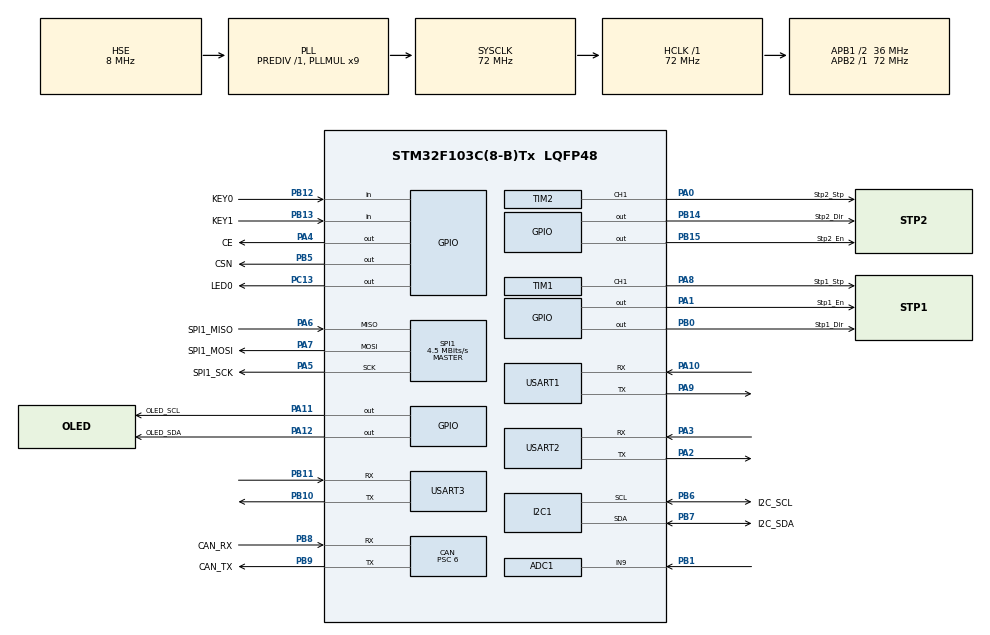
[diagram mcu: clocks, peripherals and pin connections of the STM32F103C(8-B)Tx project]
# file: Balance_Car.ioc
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ADC1.Channel-0\#ChannelRegularConversion=ADC_CHANNEL_9
ADC1.NbrOfConversionFlag=1
ADC1.Rank-0\#ChannelRegularConversion=1
ADC1.SamplingTime-0\#ChannelRegularConversion=ADC_SAMPLETIME_1CYCLE_5
ADC1.master=1
CAN.ABOM=ENABLE
CAN.BS1=CAN_BS1_9TQ
CAN.BS2=CAN_BS2_2TQ
CAN.CalculateBaudRate=499999
CAN.CalculateTimeBit=2000
CAN.CalculateTimeQuantum=166.66666666666669
CAN.NART=ENABLE
CAN.Prescaler=6
Dma.Request0=USART1_RX
Dma.Request1=USART1_TX
Dma.Request2=USART2_RX
Dma.Request3=USART2_TX
Dma.Request4=USART3_RX
Dma.Request5=USART3_TX
Dma.USART1_RX.0.Direction=DMA_PERIPH_TO_MEMORY
Dma.USART1_RX.0.Instance=DMA1_Channel5
Dma.USART1_RX.0.MemDataAlignment=DMA_MDATAALIGN_BYTE
Dma.USART1_RX.0.MemInc=DMA_MINC_ENABLE
Dma.USART1_RX.0.Mode=DMA_NORMAL
Dma.USART1_RX.0.PeriphDataAlignment=DMA_PDATAALIGN_BYTE
Dma.USART1_RX.0.PeriphInc=DMA_PINC_DISABLE
Dma.USART1_RX.0.Priority=DMA_PRIORITY_LOW
Dma.USART1_TX.1.Direction=DMA_MEMORY_TO_PERIPH
Dma.USART1_TX.1.Instance=DMA1_Channel4
Dma.USART1_TX.1.MemDataAlignment=DMA_MDATAALIGN_BYTE
Dma.USART1_TX.1.MemInc=DMA_MINC_ENABLE
Dma.USART1_TX.1.Mode=DMA_NORMAL
Dma.USART1_TX.1.PeriphDataAlignment=DMA_PDATAALIGN_BYTE
Dma.USART1_TX.1.PeriphInc=DMA_PINC_DISABLE
Dma.USART1_TX.1.Priority=DMA_PRIORITY_LOW
Dma.USART2_RX.2.Direction=DMA_PERIPH_TO_MEMORY
Dma.USART2_RX.2.Instance=DMA1_Channel6
Dma.USART2_RX.2.MemDataAlignment=DMA_MDATAALIGN_BYTE
Dma.USART2_RX.2.MemInc=DMA_MINC_ENABLE
Dma.USART2_RX.2.Mode=DMA_NORMAL
Dma.USART2_RX.2.PeriphDataAlignment=DMA_PDATAALIGN_BYTE
Dma.USART2_RX.2.PeriphInc=DMA_PINC_DISABLE
Dma.USART2_RX.2.Priority=DMA_PRIORITY_LOW
Dma.USART2_TX.3.Direction=DMA_MEMORY_TO_PERIPH
Dma.USART2_TX.3.Instance=DMA1_Channel7
Dma.USART2_TX.3.MemDataAlignment=DMA_MDATAALIGN_BYTE
Dma.USART2_TX.3.MemInc=DMA_MINC_ENABLE
Dma.USART2_TX.3.Mode=DMA_NORMAL
Dma.USART2_TX.3.PeriphDataAlignment=DMA_PDATAALIGN_BYTE
Dma.USART2_TX.3.PeriphInc=DMA_PINC_DISABLE
Dma.USART2_TX.3.Priority=DMA_PRIORITY_LOW
Dma.USART3_RX.4.Direction=DMA_PERIPH_TO_MEMORY
Dma.USART3_RX.4.Instance=DMA1_Channel3
Dma.USART3_RX.4.MemDataAlignment=DMA_MDATAALIGN_BYTE
Dma.USART3_RX.4.MemInc=DMA_MINC_ENABLE
Dma.USART3_RX.4.Mode=DMA_NORMAL
Dma.USART3_RX.4.PeriphDataAlignment=DMA_PDATAALIGN_BYTE
Dma.USART3_RX.4.PeriphInc=DMA_PINC_DISABLE
Dma.USART3_RX.4.Priority=DMA_PRIORITY_LOW
Dma.USART3_TX.5.Direction=DMA_MEMORY_TO_PERIPH
Dma.USART3_TX.5.Instance=DMA1_Channel2
Dma.USART3_TX.5.MemDataAlignment=DMA_MDATAALIGN_BYTE
Dma.USART3_TX.5.MemInc=DMA_MINC_ENABLE
Dma.USART3_TX.5.Mode=DMA_NORMAL
Dma.USART3_TX.5.PeriphDataAlignment=DMA_PDATAALIGN_BYTE
Dma.USART3_TX.5.PeriphInc=DMA_PINC_DISABLE
Dma.USART3_TX.5.Priority=DMA_PRIORITY_LOW
FREERTOS.TOTAL_HEAP_SIZE=6144
FREERTOS.Tasks01=defaultTask,24,128,StartDefaultTask,Default,NULL,Dynamic,NULL,NULL
FREERTOS.configGENERATE_RUN_TIME_STATS=1
FREERTOS.configTOTAL_HEAP_SIZE=6144
FREERTOS.configUSE_STATS_FORMATTING_FUNCTIONS=1
Mcu.Family=STM32F1
Mcu.Name=STM32F103C(8-B)Tx
Mcu.Package=LQFP48
NVIC.DMA1_Channel2_IRQn=true\:5\:0\:false\:false\:true\:true\:false\:true\:true
NVIC.DMA1_Channel3_IRQn=true\:5\:0\:false\:false\:true\:true\:false\:true\:true
NVIC.DMA1_Channel4_IRQn=true\:5\:0\:false\:false\:true\:true\:false\:true\:true
NVIC.DMA1_Channel5_IRQn=true\:5\:0\:false\:false\:true\:true\:false\:true\:true
NVIC.DMA1_Channel6_IRQn=true\:5\:0\:false\:false\:true\:true\:false\:true\:true
NVIC.DMA1_Channel7_IRQn=true\:5\:0\:false\:false\:true\:true\:false\:true\:true
NVIC.PriorityGroup=NVIC_PRIORITYGROUP_4
NVIC.TIM4_IRQn=true\:15\:0\:true\:false\:true\:false\:false\:true\:true
NVIC.TimeBase=TIM4_IRQn
NVIC.TimeBaseIP=TIM4
NVIC.USART1_IRQn=true\:5\:0\:false\:false\:true\:true\:true\:true\:true
NVIC.USART2_IRQn=true\:5\:0\:false\:false\:true\:true\:true\:true\:true
NVIC.USART3_IRQn=true\:5\:0\:false\:false\:true\:true\:false\:true\:true
NVIC.USB_LP_CAN1_RX0_IRQn=true\:5\:0\:false\:false\:true\:true\:true\:true\:true
PA0-WKUP.GPIO_Label=Stp2_Stp
PA0-WKUP.Signal=S_TIM2_CH1_ETR
PA1.GPIO_Label=Stp1_En
PA1.Signal=GPIO_Output
PA10.Mode=Asynchronous
PA10.Signal=USART1_RX
PA11.GPIO_Label=OLED_SCL
PA11.GPIO_Speed=GPIO_SPEED_FREQ_HIGH
PA11.Signal=GPIO_Output
PA12.GPIO_Label=OLED_SDA
PA12.GPIO_Speed=GPIO_SPEED_FREQ_HIGH
PA12.Signal=GPIO_Output
PA13.Mode=Serial_Wire
PA13.Signal=SYS_JTMS-SWDIO
PA14.Mode=Serial_Wire
PA14.Signal=SYS_JTCK-SWCLK
PA2.Mode=Asynchronous
PA2.Signal=USART2_TX
PA3.Mode=Asynchronous
PA3.Signal=USART2_RX
PA4.GPIO_Label=CE
PA4.Signal=GPIO_Output
PA5.GPIO_Label=SPI1_SCK
PA5.Mode=Full_Duplex_Master
PA5.Signal=SPI1_SCK
PA6.GPIO_Label=SPI1_MISO
PA6.Mode=Full_Duplex_Master
PA6.Signal=SPI1_MISO
PA7.GPIO_Label=SPI1_MOSI
PA7.Mode=Full_Duplex_Master
PA7.Signal=SPI1_MOSI
PA8.GPIO_Label=Stp1_Stp
PA8.Signal=S_TIM1_CH1
PA9.Mode=Asynchronous
PA9.Signal=USART1_TX
PB0.GPIO_Label=Stp1_Dir
PB0.Signal=GPIO_Output
PB1.Signal=ADCx_IN9
PB10.Mode=Asynchronous
PB10.Signal=USART3_TX
PB11.Mode=Asynchronous
PB11.Signal=USART3_RX
PB12.GPIO_Label=KEY0
PB12.GPIO_PuPd=GPIO_PULLUP
PB12.Signal=GPIO_Input
PB13.GPIO_Label=KEY1
PB13.GPIO_PuPd=GPIO_PULLUP
PB13.Signal=GPIO_Input
PB14.GPIO_Label=Stp2_Dir
PB14.Signal=GPIO_Output
PB15.GPIO_Label=Stp2_En
PB15.Signal=GPIO_Output
PB5.GPIO_Label=CSN
PB5.PinState=GPIO_PIN_SET
PB5.Signal=GPIO_Output
PB6.GPIO_Label=I2C_SCL
PB6.Mode=I2C
PB6.Signal=I2C1_SCL
PB7.GPIO_Label=I2C_SDA
PB7.Mode=I2C
PB7.Signal=I2C1_SDA
PB8.GPIO_Label=CAN_RX
PB8.Mode=CAN_Activate
PB8.Signal=CAN_RX
PB9.GPIO_Label=CAN_TX
PB9.Mode=CAN_Activate
PB9.Signal=CAN_TX
PC13-TAMPER-RTC.GPIO_Label=LED0
PC13-TAMPER-RTC.Signal=GPIO_Output
PC14-OSC32_IN.Mode=LSE-External-Oscillator
PC14-OSC32_IN.Signal=RCC_OSC32_IN
PC15-OSC32_OUT.Mode=LSE-External-Oscillator
PC15-OSC32_OUT.Signal=RCC_OSC32_OUT
PD0-OSC_IN.Mode=HSE-External-Oscillator
PD0-OSC_IN.Signal=RCC_OSC_IN
PD1-OSC_OUT.Mode=HSE-External-Oscillator
PD1-OSC_OUT.Signal=RCC_OSC_OUT
ProjectManager.HeapSize=0x200
ProjectManager.StackSize=0x400
ProjectManager.TargetToolchain=MDK-ARM V5.32
RCC.ADCPresc=RCC_ADCPCLK2_DIV6
RCC.AHBFreq_Value=72000000
RCC.APB1CLKDivider=RCC_HCLK_DIV2
RCC.APB1Freq_Value=36000000
RCC.APB1TimFreq_Value=72000000
RCC.APB2Freq_Value=72000000
RCC.APB2TimFreq_Value=72000000
RCC.HCLKFreq_Value=72000000
RCC.PLLMUL=RCC_PLL_MUL9
RCC.PLLSourceVirtual=RCC_PLLSOURCE_HSE
RCC.SYSCLKFreq_VALUE=72000000
RCC.SYSCLKSource=RCC_SYSCLKSOURCE_PLLCLK
RCC.USBFreq_Value=72000000
SH.ADCx_IN9.0=ADC1_IN9,IN9
SH.S_TIM1_CH1.0=TIM1_CH1,Output Compare1 CH1
SH.S_TIM2_CH1_ETR.0=TIM2_CH1,Output Compare1 CH1
SPI1.BaudRatePrescaler=SPI_BAUDRATEPRESCALER_16
SPI1.CalculateBaudRate=4.5 MBits/s
SPI1.Direction=SPI_DIRECTION_2LINES
SPI1.Mode=SPI_MODE_MASTER
SPI1.VirtualType=VM_MASTER
TIM1.Channel-Output\ Compare1\ CH1=TIM_CHANNEL_1
TIM2.Channel-Output\ Compare1\ CH1=TIM_CHANNEL_1
USART1.VirtualMode=VM_ASYNC
USART2.VirtualMode=VM_ASYNC
USART3.VirtualMode=VM_ASYNC
VP_FREERTOS_VS_CMSIS_V2.Mode=CMSIS_V2
VP_SYS_VS_tim4.Mode=TIM4
VP_TIM1_VS_ClockSourceINT.Mode=Internal
VP_TIM2_VS_ClockSourceINT.Mode=Internal
board=custom

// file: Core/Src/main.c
/* USER CODE BEGIN Header */
/**
  ******************************************************************************
  * @file           : main.c
  * @brief          : Main program body
  ******************************************************************************
  * @attention
  *
  * Copyright (c) 2026 STMicroelectronics.
  * All rights reserved.
  *
  * This software is licensed under terms that can be found in the LICENSE file
  * in the root directory of this software component.
  * If no LICENSE file comes with this software, it is provided AS-IS.
  *
  ******************************************************************************
  */
/* USER CODE END Header */
#include "main.h"
#include "cmsis_os.h"
#include "adc.h"
#include "can.h"
#include "dma.h"
#include "i2c.h"
#include "spi.h"
#include "tim.h"
#include "usart.h"
#include "gpio.h"

/* USER CODE BEGIN Includes */
#include "Initial.h"
#include "ISR.h"

/* USER CODE END Includes */

void SystemClock_Config(void);
void MX_FREERTOS_Init(void);

int main(void)
{

  /* MCU Configuration--------------------------------------------------------*/

  /* Reset of all peripherals, Initializes the Flash interface and the Systick. */
  HAL_Init();

  /* Configure the system clock */
  SystemClock_Config();

  /* Initialize all configured peripherals */
  MX_GPIO_Init();
  MX_DMA_Init();
  MX_CAN_Init();
  MX_I2C1_Init();
  MX_USART1_UART_Init();
  MX_USART2_UART_Init();
  MX_USART3_UART_Init();
  MX_ADC1_Init();
  MX_SPI1_Init();
  MX_TIM1_Init();
  MX_TIM2_Init();
  /* USER CODE BEGIN 2 */
  Hardware_Init();

  /* USER CODE END 2 */

  /* Init scheduler */
  osKernelInitialize();  /* Call init function for freertos objects (in cmsis_os2.c) */
  MX_FREERTOS_Init();

  /* Start scheduler */
  osKernelStart();

  /* We should never get here as control is now taken by the scheduler */

  /* Infinite loop */
  while (1)
  {

  }
}

void SystemClock_Config(void)
{
  RCC_OscInitTypeDef RCC_OscInitStruct = {0};
  RCC_ClkInitTypeDef RCC_ClkInitStruct = {0};
  RCC_PeriphCLKInitTypeDef PeriphClkInit = {0};

  /** Initializes the RCC Oscillators according to the specified parameters
  * in the RCC_OscInitTypeDef structure.
  */
  RCC_OscInitStruct.OscillatorType = RCC_OSCILLATORTYPE_HSE;
  RCC_OscInitStruct.HSEState = RCC_HSE_ON;
  RCC_OscInitStruct.HSEPredivValue = RCC_HSE_PREDIV_DIV1;
  RCC_OscInitStruct.HSIState = RCC_HSI_ON;
  RCC_OscInitStruct.PLL.PLLState = RCC_PLL_ON;
  RCC_OscInitStruct.PLL.PLLSource = RCC_PLLSOURCE_HSE;
  RCC_OscInitStruct.PLL.PLLMUL = RCC_PLL_MUL9;
  if (HAL_RCC_OscConfig(&RCC_OscInitStruct) != HAL_OK)
  {
    Error_Handler();
  }

  /** Initializes the CPU, AHB and APB buses clocks
  */
  RCC_ClkInitStruct.ClockType = RCC_CLOCKTYPE_HCLK|RCC_CLOCKTYPE_SYSCLK
                              |RCC_CLOCKTYPE_PCLK1|RCC_CLOCKTYPE_PCLK2;
  RCC_ClkInitStruct.SYSCLKSource = RCC_SYSCLKSOURCE_PLLCLK;
  RCC_ClkInitStruct.AHBCLKDivider = RCC_SYSCLK_DIV1;
  RCC_ClkInitStruct.APB1CLKDivider = RCC_HCLK_DIV2;
  RCC_ClkInitStruct.APB2CLKDivider = RCC_HCLK_DIV1;

  if (HAL_RCC_ClockConfig(&RCC_ClkInitStruct, FLASH_LATENCY_2) != HAL_OK)
  {
    Error_Handler();
  }
  PeriphClkInit.PeriphClockSelection = RCC_PERIPHCLK_ADC;
  PeriphClkInit.AdcClockSelection = RCC_ADCPCLK2_DIV6;
  if (HAL_RCCEx_PeriphCLKConfig(&PeriphClkInit) != HAL_OK)
  {
    Error_Handler();
  }
}

void HAL_TIM_PeriodElapsedCallback(TIM_HandleTypeDef *htim)
{
  if (htim->Instance == TIM4)
  {
    HAL_IncTick();
  }
  /* USER CODE BEGIN Callback 1 */
  ISR_TIM_Handler(htim);

  /* USER CODE END Callback 1 */
}

void Error_Handler(void)
{
  __disable_irq();
  while (1)
  {
  }
}

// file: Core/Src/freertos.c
/* USER CODE BEGIN Header */
/**
  ******************************************************************************
  * File Name          : freertos.c
  * Description        : Code for freertos applications
  ******************************************************************************
  * @attention
  *
  * Copyright (c) 2026 STMicroelectronics.
  * All rights reserved.
  *
  * This software is licensed under terms that can be found in the LICENSE file
  * in the root directory of this software component.
  * If no LICENSE file comes with this software, it is provided AS-IS.
  *
  ******************************************************************************
  */
/* USER CODE END Header */

#include "FreeRTOS.h"
#include "task.h"
#include "main.h"
#include "cmsis_os.h"

/* USER CODE BEGIN Includes */
#include "Initial.h"
#include "TaskMonitor.h"

/* USER CODE END Includes */

/* Definitions for defaultTask */
osThreadId_t defaultTaskHandle;
const osThreadAttr_t defaultTask_attributes = {
  .name = "defaultTask",
  .stack_size = 128 * 4,
  .priority = (osPriority_t) osPriorityNormal,
};

void StartDefaultTask(void *argument);

void MX_FREERTOS_Init(void); /* (MISRA C 2004 rule 8.1) */

/* Hook prototypes */
void configureTimerForRunTimeStats(void);
unsigned long getRunTimeCounterValue(void);

/* USER CODE BEGIN 1 */
/* Functions needed when configGENERATE_RUN_TIME_STATS is on */
__weak void configureTimerForRunTimeStats(void)
{
  TaskMonitor_ClockInit();
}

__weak unsigned long getRunTimeCounterValue(void)
{
  return TaskMonitor_ClockUs();
}
/* USER CODE END 1 */

void MX_FREERTOS_Init(void) {

  /* Create the thread(s) */
  /* creation of defaultTask */
  defaultTaskHandle = osThreadNew(StartDefaultTask, NULL, &defaultTask_attributes);

}

void StartDefaultTask(void *argument)
{
  /* USER CODE BEGIN StartDefaultTask */
  Msg_Init();
  Task_Init();
  vTaskDelete(NULL);
  /* USER CODE END StartDefaultTask */
}
